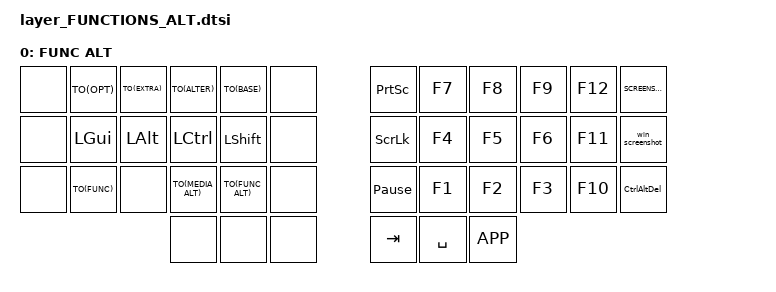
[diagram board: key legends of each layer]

/ {
    keymap {
        compatible = "zmk,keymap";

        functions_alt {
            // -----------------------------------------------------------------------------------------
            // |     |     |     |     |     |     |         | PRSC | F7 | F8 | F9  | F12 |    | 
            // |     | GUI | ALT | CTL | SFT |     |         | SCLK | F4 | F5 | F6  | F11 |    | 
            // |     |     |     |     |     |     |         | PBRK | F1 | F2 | F3  | F10 |    | 
            //                   |     |     |     |         |  TAB | SPC | APP |     

            display-name = "FUNC ALT";
            bindings = <
&none       TO(OPT)    TO(EXTRA)  TO(ALTER)      TO(BASE)      &none       &kp PRINTSCREEN  &kp F7  &kp F8  &kp F9  &kp F12  &kp K_SCREENSAVER
&none       &kp LGUI  &kp LALT  &kp LCTRL     &kp LSHFT    &none       &kp SCROLLLOCK   &kp F4  &kp F5  &kp F6  &kp F11  &win_screenshot
&none       TO(FUNC)   &none     TO(MEDIA_ALT)  TO(FUNC_ALT)  &none       &kp PAUSE_BREAK  &kp F1  &kp F2  &kp F3  &kp F10  &CtrlAltDel
                                &none         &none        &none       &kp TAB  &kp SPACE  &kp K_APP
            >;
        };
    };
};
